AUTOSAR XML (schema 4-0-3)
package /ComponentTypes
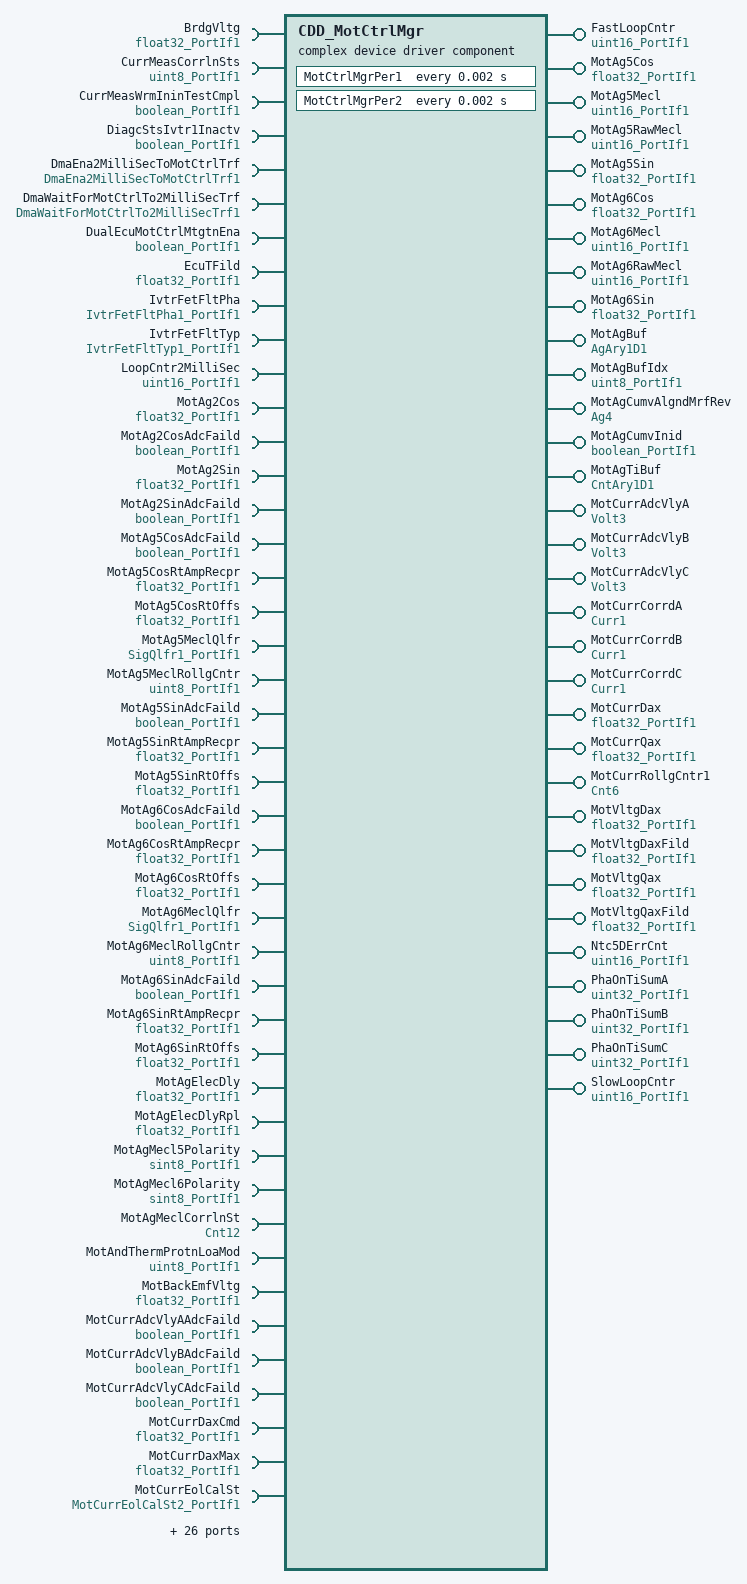
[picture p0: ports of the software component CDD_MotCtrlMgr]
  complex device driver sw component type CDD_MotCtrlMgr
    32 x provide port:
      FastLoopCntr: nonqueued-sender-com-spec{data-element=Val, init-value=0}, provided-interface=uint16_PortIf1
      MotAg5Cos: nonqueued-sender-com-spec{data-element=Val, init-value=0}, provided-interface=float32_PortIf1
      MotAg5Mecl: nonqueued-sender-com-spec{data-element=Val, init-value=0}, provided-interface=uint16_PortIf1
      MotAg5RawMecl: nonqueued-sender-com-spec{data-element=Val, init-value=0}, provided-interface=uint16_PortIf1
      MotAg5Sin: nonqueued-sender-com-spec{data-element=Val, init-value=0}, provided-interface=float32_PortIf1
      MotAg6Cos: nonqueued-sender-com-spec{data-element=Val, init-value=0}, provided-interface=float32_PortIf1
      MotAg6Mecl: nonqueued-sender-com-spec{data-element=Val, init-value=0}, provided-interface=uint16_PortIf1
      MotAg6RawMecl: nonqueued-sender-com-spec{data-element=Val, init-value=0}, provided-interface=uint16_PortIf1
      MotAg6Sin: nonqueued-sender-com-spec{data-element=Val, init-value=0}, provided-interface=float32_PortIf1
      MotAgBuf: nonqueued-sender-com-spec=data-element=Ary1D, provided-interface=AgAry1D1
      MotAgBufIdx: nonqueued-sender-com-spec{data-element=Val, init-value=0}, provided-interface=uint8_PortIf1
      MotAgCumvAlgndMrfRev: nonqueued-sender-com-spec{data-element=Val, init-value=0}, provided-interface=Ag4
      MotAgCumvInid: nonqueued-sender-com-spec{data-element=Logl, init-value=0}, provided-interface=boolean_PortIf1
      MotAgTiBuf: nonqueued-sender-com-spec=data-element=Ary1D, provided-interface=CntAry1D1
      MotCurrAdcVlyA: nonqueued-sender-com-spec{data-element=Val, init-value=0}, provided-interface=Volt3
      MotCurrAdcVlyB: nonqueued-sender-com-spec{data-element=Val, init-value=0}, provided-interface=Volt3
      MotCurrAdcVlyC: nonqueued-sender-com-spec{data-element=Val, init-value=0}, provided-interface=Volt3
      MotCurrCorrdA: nonqueued-sender-com-spec{data-element=Val, init-value=0}, provided-interface=Curr1
      MotCurrCorrdB: nonqueued-sender-com-spec{data-element=Val, init-value=0}, provided-interface=Curr1
      MotCurrCorrdC: nonqueued-sender-com-spec{data-element=Val, init-value=0}, provided-interface=Curr1
      MotCurrDax: nonqueued-sender-com-spec{data-element=Val, init-value=0}, provided-interface=float32_PortIf1
      MotCurrQax: nonqueued-sender-com-spec{data-element=Val, init-value=0}, provided-interface=float32_PortIf1
      MotCurrRollgCntr1: nonqueued-sender-com-spec{data-element=Val, init-value=0}, provided-interface=Cnt6
      MotVltgDax: nonqueued-sender-com-spec{data-element=Val, init-value=0}, provided-interface=float32_PortIf1
      MotVltgDaxFild: nonqueued-sender-com-spec{data-element=Val, init-value=0}, provided-interface=float32_PortIf1
      MotVltgQax: nonqueued-sender-com-spec{data-element=Val, init-value=0}, provided-interface=float32_PortIf1
      MotVltgQaxFild: nonqueued-sender-com-spec{data-element=Val, init-value=0}, provided-interface=float32_PortIf1
      Ntc5DErrCnt: nonqueued-sender-com-spec{data-element=Val, init-value=0}, provided-interface=uint16_PortIf1
      PhaOnTiSumA: nonqueued-sender-com-spec{data-element=Val, init-value=0}, provided-interface=uint32_PortIf1
      PhaOnTiSumB: nonqueued-sender-com-spec{data-element=Val, init-value=0}, provided-interface=uint32_PortIf1
      PhaOnTiSumC: nonqueued-sender-com-spec{data-element=Val, init-value=0}, provided-interface=uint32_PortIf1
      SlowLoopCntr: nonqueued-sender-com-spec{data-element=Val, init-value=0}, provided-interface=uint16_PortIf1
    70 x require port:
      BrdgVltg: nonqueued-receiver-com-spec{data-element=Val, filter=data-filter-type=ALWAYS, init-value=6}, required-interface=float32_PortIf1
      CurrMeasCorrlnSts: nonqueued-receiver-com-spec{data-element=Val, filter=data-filter-type=ALWAYS, init-value=63}, required-interface=uint8_PortIf1
      CurrMeasWrmIninTestCmpl: nonqueued-receiver-com-spec{data-element=Logl, filter=data-filter-type=ALWAYS, init-value=0}, required-interface=boolean_PortIf1
      DiagcStsIvtr1Inactv: nonqueued-receiver-com-spec{data-element=Logl, filter=data-filter-type=ALWAYS, init-value=0}, required-interface=boolean_PortIf1
      DmaEna2MilliSecToMotCtrlTrf: client-com-spec=Oper, required-interface=DmaEna2MilliSecToMotCtrlTrf1
      DmaWaitForMotCtrlTo2MilliSecTrf: client-com-spec=Oper, required-interface=DmaWaitForMotCtrlTo2MilliSecTrf1
      DualEcuMotCtrlMtgtnEna: nonqueued-receiver-com-spec{data-element=Logl, filter=data-filter-type=ALWAYS, init-value=0}, required-interface=boolean_PortIf1
      EcuTFild: nonqueued-receiver-com-spec{data-element=Val, filter=data-filter-type=ALWAYS, init-value=25}, required-interface=float32_PortIf1
      IvtrFetFltPha: nonqueued-receiver-com-spec{data-element=Val, filter=data-filter-type=ALWAYS, init-value=0}, required-interface=IvtrFetFltPha1_PortIf1
      IvtrFetFltTyp: nonqueued-receiver-com-spec{data-element=Val, filter=data-filter-type=ALWAYS, init-value=0}, required-interface=IvtrFetFltTyp1_PortIf1
      LoopCntr2MilliSec: nonqueued-receiver-com-spec{data-element=Val, filter=data-filter-type=ALWAYS, init-value=0}, required-interface=uint16_PortIf1
      MotAg2Cos: nonqueued-receiver-com-spec{data-element=Val, filter=data-filter-type=ALWAYS, init-value=0}, required-interface=float32_PortIf1
      MotAg2CosAdcFaild: nonqueued-receiver-com-spec{data-element=Logl, filter=data-filter-type=ALWAYS, init-value=0}, required-interface=boolean_PortIf1
      MotAg2Sin: nonqueued-receiver-com-spec{data-element=Val, filter=data-filter-type=ALWAYS, init-value=0}, required-interface=float32_PortIf1
      MotAg2SinAdcFaild: nonqueued-receiver-com-spec{data-element=Logl, filter=data-filter-type=ALWAYS, init-value=0}, required-interface=boolean_PortIf1
      MotAg5CosAdcFaild: nonqueued-receiver-com-spec{data-element=Logl, filter=data-filter-type=ALWAYS, init-value=0}, required-interface=boolean_PortIf1
      MotAg5CosRtAmpRecpr: nonqueued-receiver-com-spec{data-element=Val, filter=data-filter-type=ALWAYS, init-value=0}, required-interface=float32_PortIf1
      MotAg5CosRtOffs: nonqueued-receiver-com-spec{data-element=Val, filter=data-filter-type=ALWAYS, init-value=0}, required-interface=float32_PortIf1
      MotAg5MeclQlfr: nonqueued-receiver-com-spec{data-element=Val, filter=data-filter-type=ALWAYS, init-value=0}, required-interface=SigQlfr1_PortIf1
      MotAg5MeclRollgCntr: nonqueued-receiver-com-spec{data-element=Val, filter=data-filter-type=ALWAYS, init-value=0}, required-interface=uint8_PortIf1
      MotAg5SinAdcFaild: nonqueued-receiver-com-spec{data-element=Logl, filter=data-filter-type=ALWAYS, init-value=0}, required-interface=boolean_PortIf1
      MotAg5SinRtAmpRecpr: nonqueued-receiver-com-spec{data-element=Val, filter=data-filter-type=ALWAYS, init-value=0}, required-interface=float32_PortIf1
      MotAg5SinRtOffs: nonqueued-receiver-com-spec{data-element=Val, filter=data-filter-type=ALWAYS, init-value=0}, required-interface=float32_PortIf1
      MotAg6CosAdcFaild: nonqueued-receiver-com-spec{data-element=Logl, filter=data-filter-type=ALWAYS, init-value=0}, required-interface=boolean_PortIf1
      MotAg6CosRtAmpRecpr: nonqueued-receiver-com-spec{data-element=Val, filter=data-filter-type=ALWAYS, init-value=0}, required-interface=float32_PortIf1
      MotAg6CosRtOffs: nonqueued-receiver-com-spec{data-element=Val, filter=data-filter-type=ALWAYS, init-value=0}, required-interface=float32_PortIf1
      MotAg6MeclQlfr: nonqueued-receiver-com-spec{data-element=Val, filter=data-filter-type=ALWAYS, init-value=0}, required-interface=SigQlfr1_PortIf1
      MotAg6MeclRollgCntr: nonqueued-receiver-com-spec{data-element=Val, filter=data-filter-type=ALWAYS, init-value=0}, required-interface=uint8_PortIf1
      MotAg6SinAdcFaild: nonqueued-receiver-com-spec{data-element=Logl, filter=data-filter-type=ALWAYS, init-value=0}, required-interface=boolean_PortIf1
      MotAg6SinRtAmpRecpr: nonqueued-receiver-com-spec{data-element=Val, filter=data-filter-type=ALWAYS, init-value=0}, required-interface=float32_PortIf1
      MotAg6SinRtOffs: nonqueued-receiver-com-spec{data-element=Val, filter=data-filter-type=ALWAYS, init-value=0}, required-interface=float32_PortIf1
      MotAgElecDly: nonqueued-receiver-com-spec{data-element=Val, filter=data-filter-type=ALWAYS, init-value=0}, required-interface=float32_PortIf1
      MotAgElecDlyRpl: nonqueued-receiver-com-spec{data-element=Val, filter=data-filter-type=ALWAYS, init-value=0}, required-interface=float32_PortIf1
      MotAgMecl5Polarity: nonqueued-receiver-com-spec{data-element=Val, filter=data-filter-type=ALWAYS, init-value=0}, required-interface=sint8_PortIf1
      MotAgMecl6Polarity: nonqueued-receiver-com-spec{data-element=Val, filter=data-filter-type=ALWAYS, init-value=0}, required-interface=sint8_PortIf1
      MotAgMeclCorrlnSt: nonqueued-receiver-com-spec{data-element=Val, filter=data-filter-type=ALWAYS, init-value=7}, required-interface=Cnt12
      MotAndThermProtnLoaMod: nonqueued-receiver-com-spec{data-element=Val, filter=data-filter-type=ALWAYS, init-value=0}, required-interface=uint8_PortIf1
      MotBackEmfVltg: nonqueued-receiver-com-spec{data-element=Val, filter=data-filter-type=ALWAYS, init-value=0}, required-interface=float32_PortIf1
      MotCurrAdcVlyAAdcFaild: nonqueued-receiver-com-spec{data-element=Logl, filter=data-filter-type=ALWAYS, init-value=0}, required-interface=boolean_PortIf1
      MotCurrAdcVlyBAdcFaild: nonqueued-receiver-com-spec{data-element=Logl, filter=data-filter-type=ALWAYS, init-value=0}, required-interface=boolean_PortIf1
      MotCurrAdcVlyCAdcFaild: nonqueued-receiver-com-spec{data-element=Logl, filter=data-filter-type=ALWAYS, init-value=0}, required-interface=boolean_PortIf1
      MotCurrDaxCmd: nonqueued-receiver-com-spec{data-element=Val, filter=data-filter-type=ALWAYS, init-value=0}, required-interface=float32_PortIf1
      MotCurrDaxMax: nonqueued-receiver-com-spec{data-element=Val, filter=data-filter-type=ALWAYS, init-value=0}, required-interface=float32_PortIf1
      MotCurrEolCalSt: nonqueued-receiver-com-spec{data-element=Val, filter=data-filter-type=ALWAYS, init-value=0}, required-interface=MotCurrEolCalSt2_PortIf1
      MotCurrQaxCmd: nonqueued-receiver-com-spec{data-element=Val, filter=data-filter-type=ALWAYS, init-value=0}, required-interface=float32_PortIf1
      MotCurrQaxToMotTqGain: nonqueued-receiver-com-spec{data-element=Val, filter=data-filter-type=ALWAYS, init-value=0.021651}, required-interface=float32_PortIf1
      MotCurrQlfr1: nonqueued-receiver-com-spec{data-element=Val, filter=data-filter-type=ALWAYS, init-value=0}, required-interface=SigQlfr1
      MotDampgDax: nonqueued-receiver-com-spec{data-element=Val, filter=data-filter-type=ALWAYS, init-value=0}, required-interface=float32_PortIf1
      MotDampgQax: nonqueued-receiver-com-spec{data-element=Val, filter=data-filter-type=ALWAYS, init-value=0}, required-interface=float32_PortIf1
      MotElecMeclPolarity: nonqueued-receiver-com-spec{data-element=Val, filter=data-filter-type=ALWAYS}, required-interface=sint8_PortIf1
      MotInduDaxEstimdIvs: nonqueued-receiver-com-spec{data-element=Val, filter=data-filter-type=ALWAYS, init-value=0}, required-interface=float32_PortIf1
      MotInduQaxEstimdIvs: nonqueued-receiver-com-spec{data-element=Val, filter=data-filter-type=ALWAYS, init-value=0}, required-interface=float32_PortIf1
      MotIntglGainDax: nonqueued-receiver-com-spec{data-element=Val, filter=data-filter-type=ALWAYS, init-value=0}, required-interface=float32_PortIf1
      MotIntglGainQax: nonqueued-receiver-com-spec{data-element=Val, filter=data-filter-type=ALWAYS, init-value=0}, required-interface=float32_PortIf1
      MotPropGainDax: nonqueued-receiver-com-spec{data-element=Val, filter=data-filter-type=ALWAYS, init-value=0}, required-interface=float32_PortIf1
      MotPropGainQax: nonqueued-receiver-com-spec{data-element=Val, filter=data-filter-type=ALWAYS, init-value=0}, required-interface=float32_PortIf1
      MotReacncDax: nonqueued-receiver-com-spec{data-element=Val, filter=data-filter-type=ALWAYS, init-value=0}, required-interface=float32_PortIf1
      MotReacncQax: nonqueued-receiver-com-spec{data-element=Val, filter=data-filter-type=ALWAYS, init-value=0}, required-interface=float32_PortIf1
      MotREstimd: nonqueued-receiver-com-spec{data-element=Val, filter=data-filter-type=ALWAYS, init-value=0}, required-interface=float32_PortIf1
      MotTqRplCoggOrder1Mgn: nonqueued-receiver-com-spec{data-element=Val, filter=data-filter-type=ALWAYS, init-value=0}, required-interface=float32_PortIf1
      MotTqRplCoggOrder1Pha: nonqueued-receiver-com-spec{data-element=Val, filter=data-filter-type=ALWAYS, init-value=0}, required-interface=float32_PortIf1
      MotTqRplCoggOrder2Mgn: nonqueued-receiver-com-spec{data-element=Val, filter=data-filter-type=ALWAYS, init-value=0}, required-interface=float32_PortIf1
      MotTqRplCoggOrder2Pha: nonqueued-receiver-com-spec{data-element=Val, filter=data-filter-type=ALWAYS, init-value=0}, required-interface=float32_PortIf1
      MotTqRplCoggOrder3Mgn: nonqueued-receiver-com-spec{data-element=Val, filter=data-filter-type=ALWAYS, init-value=0}, required-interface=float32_PortIf1
      MotTqRplCoggOrder3Pha: nonqueued-receiver-com-spec{data-element=Val, filter=data-filter-type=ALWAYS, init-value=0}, required-interface=float32_PortIf1
      MotVelMrf: nonqueued-receiver-com-spec{data-element=Val, filter=data-filter-type=ALWAYS, init-value=0}, required-interface=float32_PortIf1
      MotVltgDaxFf: nonqueued-receiver-com-spec{data-element=Val, filter=data-filter-type=ALWAYS, init-value=0}, required-interface=float32_PortIf1
      MotVltgQaxFf: nonqueued-receiver-com-spec{data-element=Val, filter=data-filter-type=ALWAYS, init-value=0}, required-interface=float32_PortIf1
      SysSt: nonqueued-receiver-com-spec{data-element=Val, filter=data-filter-type=ALWAYS, init-value=3}, required-interface=SysSt1
      VehSpd: nonqueued-receiver-com-spec{data-element=Val, filter=data-filter-type=ALWAYS, init-value=0}, required-interface=float32_PortIf1
    behavior CDD_MotCtrlMgr_InternalBehavior: data-type-mapping=Nexteer
      timing event TMT_MotCtrlMgrPer1: start-on-event=MotCtrlMgrPer1, period=0.002
      timing event TMT_MotCtrlMgrPer2: start-on-event=MotCtrlMgrPer2, period=0.002
      port-api-options:
        enable-take-address=false, indirect-api=false, port=BrdgVltg
        enable-take-address=false, indirect-api=false, port=CurrMeasCorrlnSts
        enable-take-address=false, indirect-api=false, port=CurrMeasWrmIninTestCmpl
        enable-take-address=false, indirect-api=false, port=DiagcStsIvtr1Inactv
        enable-take-address=false, indirect-api=false, port=DmaEna2MilliSecToMotCtrlTrf
        enable-take-address=false, indirect-api=false, port=DmaWaitForMotCtrlTo2MilliSecTrf
        enable-take-address=false, indirect-api=false, port=DualEcuMotCtrlMtgtnEna
        enable-take-address=false, indirect-api=false, port=EcuTFild
        enable-take-address=false, indirect-api=false, port=FastLoopCntr
        enable-take-address=false, indirect-api=false, port=IvtrFetFltPha
        enable-take-address=false, indirect-api=false, port=IvtrFetFltTyp
        enable-take-address=false, indirect-api=false, port=LoopCntr2MilliSec
        enable-take-address=false, indirect-api=false, port=MotAg2Cos
        enable-take-address=false, indirect-api=false, port=MotAg2CosAdcFaild
        enable-take-address=false, indirect-api=false, port=MotAg2Sin
        enable-take-address=false, indirect-api=false, port=MotAg2SinAdcFaild
        enable-take-address=false, indirect-api=false, port=MotAg5Cos
        enable-take-address=false, indirect-api=false, port=MotAg5CosAdcFaild
        enable-take-address=false, indirect-api=false, port=MotAg5CosRtAmpRecpr
        enable-take-address=false, indirect-api=false, port=MotAg5CosRtOffs
        enable-take-address=false, indirect-api=false, port=MotAg5Mecl
        enable-take-address=false, indirect-api=false, port=MotAg5MeclQlfr
        enable-take-address=false, indirect-api=false, port=MotAg5MeclRollgCntr
        enable-take-address=false, indirect-api=false, port=MotAg5RawMecl
        enable-take-address=false, indirect-api=false, port=MotAg5Sin
        enable-take-address=false, indirect-api=false, port=MotAg5SinAdcFaild
        enable-take-address=false, indirect-api=false, port=MotAg5SinRtAmpRecpr
        enable-take-address=false, indirect-api=false, port=MotAg5SinRtOffs
        enable-take-address=false, indirect-api=false, port=MotAg6Cos
        enable-take-address=false, indirect-api=false, port=MotAg6CosAdcFaild
        enable-take-address=false, indirect-api=false, port=MotAg6CosRtAmpRecpr
        enable-take-address=false, indirect-api=false, port=MotAg6CosRtOffs
        enable-take-address=false, indirect-api=false, port=MotAg6Mecl
        enable-take-address=false, indirect-api=false, port=MotAg6MeclQlfr
        enable-take-address=false, indirect-api=false, port=MotAg6MeclRollgCntr
        enable-take-address=false, indirect-api=false, port=MotAg6RawMecl
        enable-take-address=false, indirect-api=false, port=MotAg6Sin
        enable-take-address=false, indirect-api=false, port=MotAg6SinAdcFaild
        enable-take-address=false, indirect-api=false, port=MotAg6SinRtAmpRecpr
        enable-take-address=false, indirect-api=false, port=MotAg6SinRtOffs
        enable-take-address=false, indirect-api=false, port=MotAgBuf
        enable-take-address=false, indirect-api=false, port=MotAgBufIdx
        enable-take-address=false, indirect-api=false, port=MotAgCumvAlgndMrfRev
        enable-take-address=false, indirect-api=false, port=MotAgCumvInid
        enable-take-address=false, indirect-api=false, port=MotAgElecDly
        enable-take-address=false, indirect-api=false, port=MotAgElecDlyRpl
        enable-take-address=false, indirect-api=false, port=MotAgMecl5Polarity
        enable-take-address=false, indirect-api=false, port=MotAgMecl6Polarity
        enable-take-address=false, indirect-api=false, port=MotAgMeclCorrlnSt
        enable-take-address=false, indirect-api=false, port=MotAgTiBuf
        enable-take-address=false, indirect-api=false, port=MotAndThermProtnLoaMod
        enable-take-address=false, indirect-api=false, port=MotBackEmfVltg
        enable-take-address=false, indirect-api=false, port=MotCurrAdcVlyA
        enable-take-address=false, indirect-api=false, port=MotCurrAdcVlyAAdcFaild
        enable-take-address=false, indirect-api=false, port=MotCurrAdcVlyB
        enable-take-address=false, indirect-api=false, port=MotCurrAdcVlyBAdcFaild
        enable-take-address=false, indirect-api=false, port=MotCurrAdcVlyC
        enable-take-address=false, indirect-api=false, port=MotCurrAdcVlyCAdcFaild
        enable-take-address=false, indirect-api=false, port=MotCurrCorrdA
        enable-take-address=false, indirect-api=false, port=MotCurrCorrdB
        enable-take-address=false, indirect-api=false, port=MotCurrCorrdC
        enable-take-address=false, indirect-api=false, port=MotCurrDax
        enable-take-address=false, indirect-api=false, port=MotCurrDaxCmd
        enable-take-address=false, indirect-api=false, port=MotCurrDaxMax
        enable-take-address=false, indirect-api=false, port=MotCurrEolCalSt
        enable-take-address=false, indirect-api=false, port=MotCurrQax
        enable-take-address=false, indirect-api=false, port=MotCurrQaxCmd
        enable-take-address=false, indirect-api=false, port=MotCurrQaxToMotTqGain
        enable-take-address=false, indirect-api=false, port=MotCurrQlfr1
        enable-take-address=false, indirect-api=false, port=MotCurrRollgCntr1
        enable-take-address=false, indirect-api=false, port=MotDampgDax
        enable-take-address=false, indirect-api=false, port=MotDampgQax
        enable-take-address=false, indirect-api=false, port=MotElecMeclPolarity
        enable-take-address=false, indirect-api=false, port=MotInduDaxEstimdIvs
        enable-take-address=false, indirect-api=false, port=MotInduQaxEstimdIvs
        enable-take-address=false, indirect-api=false, port=MotIntglGainDax
        enable-take-address=false, indirect-api=false, port=MotIntglGainQax
        enable-take-address=false, indirect-api=false, port=MotPropGainDax
        enable-take-address=false, indirect-api=false, port=MotPropGainQax
        enable-take-address=false, indirect-api=false, port=MotReacncDax
        enable-take-address=false, indirect-api=false, port=MotReacncQax
        enable-take-address=false, indirect-api=false, port=MotREstimd
        enable-take-address=false, indirect-api=false, port=MotTqRplCoggOrder1Mgn
        enable-take-address=false, indirect-api=false, port=MotTqRplCoggOrder1Pha
        enable-take-address=false, indirect-api=false, port=MotTqRplCoggOrder2Mgn
        enable-take-address=false, indirect-api=false, port=MotTqRplCoggOrder2Pha
        enable-take-address=false, indirect-api=false, port=MotTqRplCoggOrder3Mgn
        enable-take-address=false, indirect-api=false, port=MotTqRplCoggOrder3Pha
        enable-take-address=false, indirect-api=false, port=MotVelMrf
        enable-take-address=false, indirect-api=false, port=MotVltgDax
        enable-take-address=false, indirect-api=false, port=MotVltgDaxFf
        enable-take-address=false, indirect-api=false, port=MotVltgDaxFild
        enable-take-address=false, indirect-api=false, port=MotVltgQax
        enable-take-address=false, indirect-api=false, port=MotVltgQaxFf
        enable-take-address=false, indirect-api=false, port=MotVltgQaxFild
        enable-take-address=false, indirect-api=false, port=Ntc5DErrCnt
        enable-take-address=false, indirect-api=false, port=PhaOnTiSumA
        enable-take-address=false, indirect-api=false, port=PhaOnTiSumB
        enable-take-address=false, indirect-api=false, port=PhaOnTiSumC
        enable-take-address=false, indirect-api=false, port=SlowLoopCntr
        enable-take-address=false, indirect-api=false, port=SysSt
        enable-take-address=false, indirect-api=false, port=VehSpd
      runnable MotCtrlMgrPer1
        data-send-points:
          32 x access:
            SEND_FastLoopCntr_Val: accessed-variable=FastLoopCntr.Val
            SEND_MotAg5Cos_Val: accessed-variable=MotAg5Cos.Val
            SEND_MotAg5Mecl_Val: accessed-variable=MotAg5Mecl.Val
            SEND_MotAg5RawMecl_Val: accessed-variable=MotAg5RawMecl.Val
            SEND_MotAg5Sin_Val: accessed-variable=MotAg5Sin.Val
            SEND_MotAg6Cos_Val: accessed-variable=MotAg6Cos.Val
            SEND_MotAg6Mecl_Val: accessed-variable=MotAg6Mecl.Val
            SEND_MotAg6RawMecl_Val: accessed-variable=MotAg6RawMecl.Val
            SEND_MotAg6Sin_Val: accessed-variable=MotAg6Sin.Val
            SEND_MotAgBuf_Ary1D: accessed-variable=MotAgBuf.Ary1D
            SEND_MotAgBufIdx_Val: accessed-variable=MotAgBufIdx.Val
            SEND_MotAgCumvAlgndMrfRev_Val: accessed-variable=MotAgCumvAlgndMrfRev.Val
            SEND_MotAgCumvInid_Logl: accessed-variable=MotAgCumvInid.Logl
            SEND_MotAgTiBuf_Ary1D: accessed-variable=MotAgTiBuf.Ary1D
            SEND_MotCurrAdcVlyA_Val: accessed-variable=MotCurrAdcVlyA.Val
            SEND_MotCurrAdcVlyB_Val: accessed-variable=MotCurrAdcVlyB.Val
            SEND_MotCurrAdcVlyC_Val: accessed-variable=MotCurrAdcVlyC.Val
            SEND_MotCurrCorrdA_Val: accessed-variable=MotCurrCorrdA.Val
            SEND_MotCurrCorrdB_Val: accessed-variable=MotCurrCorrdB.Val
            SEND_MotCurrCorrdC_Val: accessed-variable=MotCurrCorrdC.Val
            SEND_MotCurrDax_Val: accessed-variable=MotCurrDax.Val
            SEND_MotCurrQax_Val: accessed-variable=MotCurrQax.Val
            SEND_MotCurrRollgCntr1_Val: accessed-variable=MotCurrRollgCntr1.Val
            SEND_MotVltgDax_Val: accessed-variable=MotVltgDax.Val
            SEND_MotVltgDaxFild_Val: accessed-variable=MotVltgDaxFild.Val
            SEND_MotVltgQax_Val: accessed-variable=MotVltgQax.Val
            SEND_MotVltgQaxFild_Val: accessed-variable=MotVltgQaxFild.Val
            SEND_Ntc5DErrCnt_Val: accessed-variable=Ntc5DErrCnt.Val
            SEND_PhaOnTiSumA_Val: accessed-variable=PhaOnTiSumA.Val
            SEND_PhaOnTiSumB_Val: accessed-variable=PhaOnTiSumB.Val
            SEND_PhaOnTiSumC_Val: accessed-variable=PhaOnTiSumC.Val
            SEND_SlowLoopCntr_Val: accessed-variable=SlowLoopCntr.Val
        sync call SC_DmaWaitForMotCtrlTo2MilliSecTrf_Oper: operation=DmaWaitForMotCtrlTo2MilliSecTrf.Oper, timeout=0
      runnable MotCtrlMgrPer2
        data-receive-point-by-arguments:
          68 x access:
            REC_BrdgVltg_Val: accessed-variable=BrdgVltg.Val
            REC_CurrMeasCorrlnSts_Val: accessed-variable=CurrMeasCorrlnSts.Val
            REC_DiagcStsIvtr1Inactv_Logl: accessed-variable=DiagcStsIvtr1Inactv.Logl
            REC_DualEcuMotCtrlMtgtnEna_Logl: accessed-variable=DualEcuMotCtrlMtgtnEna.Logl
            REC_EcuTFild_Val: accessed-variable=EcuTFild.Val
            REC_IvtrFetFltPha_Val: accessed-variable=IvtrFetFltPha.Val
            REC_IvtrFetFltTyp_Val: accessed-variable=IvtrFetFltTyp.Val
            REC_LoopCntr2MilliSec_Val: accessed-variable=LoopCntr2MilliSec.Val
            REC_MotAg2Cos_Val: accessed-variable=MotAg2Cos.Val
            REC_MotAg2CosAdcFaild_Logl: accessed-variable=MotAg2CosAdcFaild.Logl
            REC_MotAg2Sin_Val: accessed-variable=MotAg2Sin.Val
            REC_MotAg2SinAdcFaild_Logl: accessed-variable=MotAg2SinAdcFaild.Logl
            REC_MotAg5CosAdcFaild_Logl: accessed-variable=MotAg5CosAdcFaild.Logl
            REC_MotAg5CosRtAmpRecpr_Val: accessed-variable=MotAg5CosRtAmpRecpr.Val
            REC_MotAg5CosRtOffs_Val: accessed-variable=MotAg5CosRtOffs.Val
            REC_MotAg5MeclQlfr_Val: accessed-variable=MotAg5MeclQlfr.Val
            REC_MotAg5MeclRollgCntr_Val: accessed-variable=MotAg5MeclRollgCntr.Val
            REC_MotAg5SinAdcFaild_Logl: accessed-variable=MotAg5SinAdcFaild.Logl
            REC_MotAg5SinRtAmpRecpr_Val: accessed-variable=MotAg5SinRtAmpRecpr.Val
            REC_MotAg5SinRtOffs_Val: accessed-variable=MotAg5SinRtOffs.Val
            REC_MotAg6CosAdcFaild_Logl: accessed-variable=MotAg6CosAdcFaild.Logl
            REC_MotAg6CosRtAmpRecpr_Val: accessed-variable=MotAg6CosRtAmpRecpr.Val
            REC_MotAg6CosRtOffs_Val: accessed-variable=MotAg6CosRtOffs.Val
            REC_MotAg6MeclQlfr_Val: accessed-variable=MotAg6MeclQlfr.Val
            REC_MotAg6MeclRollgCntr_Val: accessed-variable=MotAg6MeclRollgCntr.Val
            REC_MotAg6SinAdcFaild_Logl: accessed-variable=MotAg6SinAdcFaild.Logl
            REC_MotAg6SinRtAmpRecpr_Val: accessed-variable=MotAg6SinRtAmpRecpr.Val
            REC_MotAg6SinRtOffs_Val: accessed-variable=MotAg6SinRtOffs.Val
            REC_MotAgElecDly_Val: accessed-variable=MotAgElecDly.Val
            REC_MotAgElecDlyRpl_Val: accessed-variable=MotAgElecDlyRpl.Val
            REC_MotAgMecl5Polarity_Val: accessed-variable=MotAgMecl5Polarity.Val
            REC_MotAgMecl6Polarity_Val: accessed-variable=MotAgMecl6Polarity.Val
            REC_MotAgMeclCorrlnSt_Val: accessed-variable=MotAgMeclCorrlnSt.Val
            REC_MotAndThermProtnLoaMod_Val: accessed-variable=MotAndThermProtnLoaMod.Val
            REC_MotBackEmfVltg_Val: accessed-variable=MotBackEmfVltg.Val
            REC_MotCtrlCurrMeasWrmIninTestCmpl_Logl: accessed-variable=CurrMeasWrmIninTestCmpl.Logl
            REC_MotCurrAdcVlyAAdcFaild_Logl: accessed-variable=MotCurrAdcVlyAAdcFaild.Logl
            REC_MotCurrAdcVlyBAdcFaild_Logl: accessed-variable=MotCurrAdcVlyBAdcFaild.Logl
            REC_MotCurrAdcVlyCAdcFaild_Logl: accessed-variable=MotCurrAdcVlyCAdcFaild.Logl
            REC_MotCurrDaxCmd_Val: accessed-variable=MotCurrDaxCmd.Val
            REC_MotCurrDaxMax_Val: accessed-variable=MotCurrDaxMax.Val
            REC_MotCurrEolCalSt_Val: accessed-variable=MotCurrEolCalSt.Val
            REC_MotCurrQaxCmd_Val: accessed-variable=MotCurrQaxCmd.Val
            REC_MotCurrQaxToMotTqGain_Val: accessed-variable=MotCurrQaxToMotTqGain.Val
            REC_MotCurrQlfr1_Val: accessed-variable=MotCurrQlfr1.Val
            REC_MotDampgDax_Val: accessed-variable=MotDampgDax.Val
            REC_MotDampgQax_Val: accessed-variable=MotDampgQax.Val
            REC_MotElecMeclPolarity_Val: accessed-variable=MotElecMeclPolarity.Val
            REC_MotInduDaxEstimdIvs_Val: accessed-variable=MotInduDaxEstimdIvs.Val
            REC_MotInduQaxEstimdIvs_Val: accessed-variable=MotInduQaxEstimdIvs.Val
            REC_MotIntglGainDax_Val: accessed-variable=MotIntglGainDax.Val
            REC_MotIntglGainQax_Val: accessed-variable=MotIntglGainQax.Val
            REC_MotPropGainDax_Val: accessed-variable=MotPropGainDax.Val
            REC_MotPropGainQax_Val: accessed-variable=MotPropGainQax.Val
            REC_MotReacncDax_Val: accessed-variable=MotReacncDax.Val
            REC_MotReacncQax_Val: accessed-variable=MotReacncQax.Val
            REC_MotREstimd_Val: accessed-variable=MotREstimd.Val
            REC_MotTqRplCoggOrder1Mgn_Val: accessed-variable=MotTqRplCoggOrder1Mgn.Val
            REC_MotTqRplCoggOrder1Pha_Val: accessed-variable=MotTqRplCoggOrder1Pha.Val
            REC_MotTqRplCoggOrder2Mgn_Val: accessed-variable=MotTqRplCoggOrder2Mgn.Val
            REC_MotTqRplCoggOrder2Pha_Val: accessed-variable=MotTqRplCoggOrder2Pha.Val
            REC_MotTqRplCoggOrder3Mgn_Val: accessed-variable=MotTqRplCoggOrder3Mgn.Val
            REC_MotTqRplCoggOrder3Pha_Val: accessed-variable=MotTqRplCoggOrder3Pha.Val
            REC_MotVelMrf_Val: accessed-variable=MotVelMrf.Val
            REC_MotVltgDaxFf_Val: accessed-variable=MotVltgDaxFf.Val
            REC_MotVltgQaxFf_Val: accessed-variable=MotVltgQaxFf.Val
            REC_SysSt_Val: accessed-variable=SysSt.Val
            REC_VehSpd_Val: accessed-variable=VehSpd.Val
        sync call SC_DmaEna2MilliSecToMotCtrlTrf_Oper: operation=DmaEna2MilliSecToMotCtrlTrf.Oper, timeout=0
  swc implementation CDD_MotCtrlMgr_Implementation: behavior=CDD_MotCtrlMgr_InternalBehavior
    code-descriptors:
      code Default: artifact-descriptors=autosar-engineering-object={short-label=Default, category=SWSRC}
